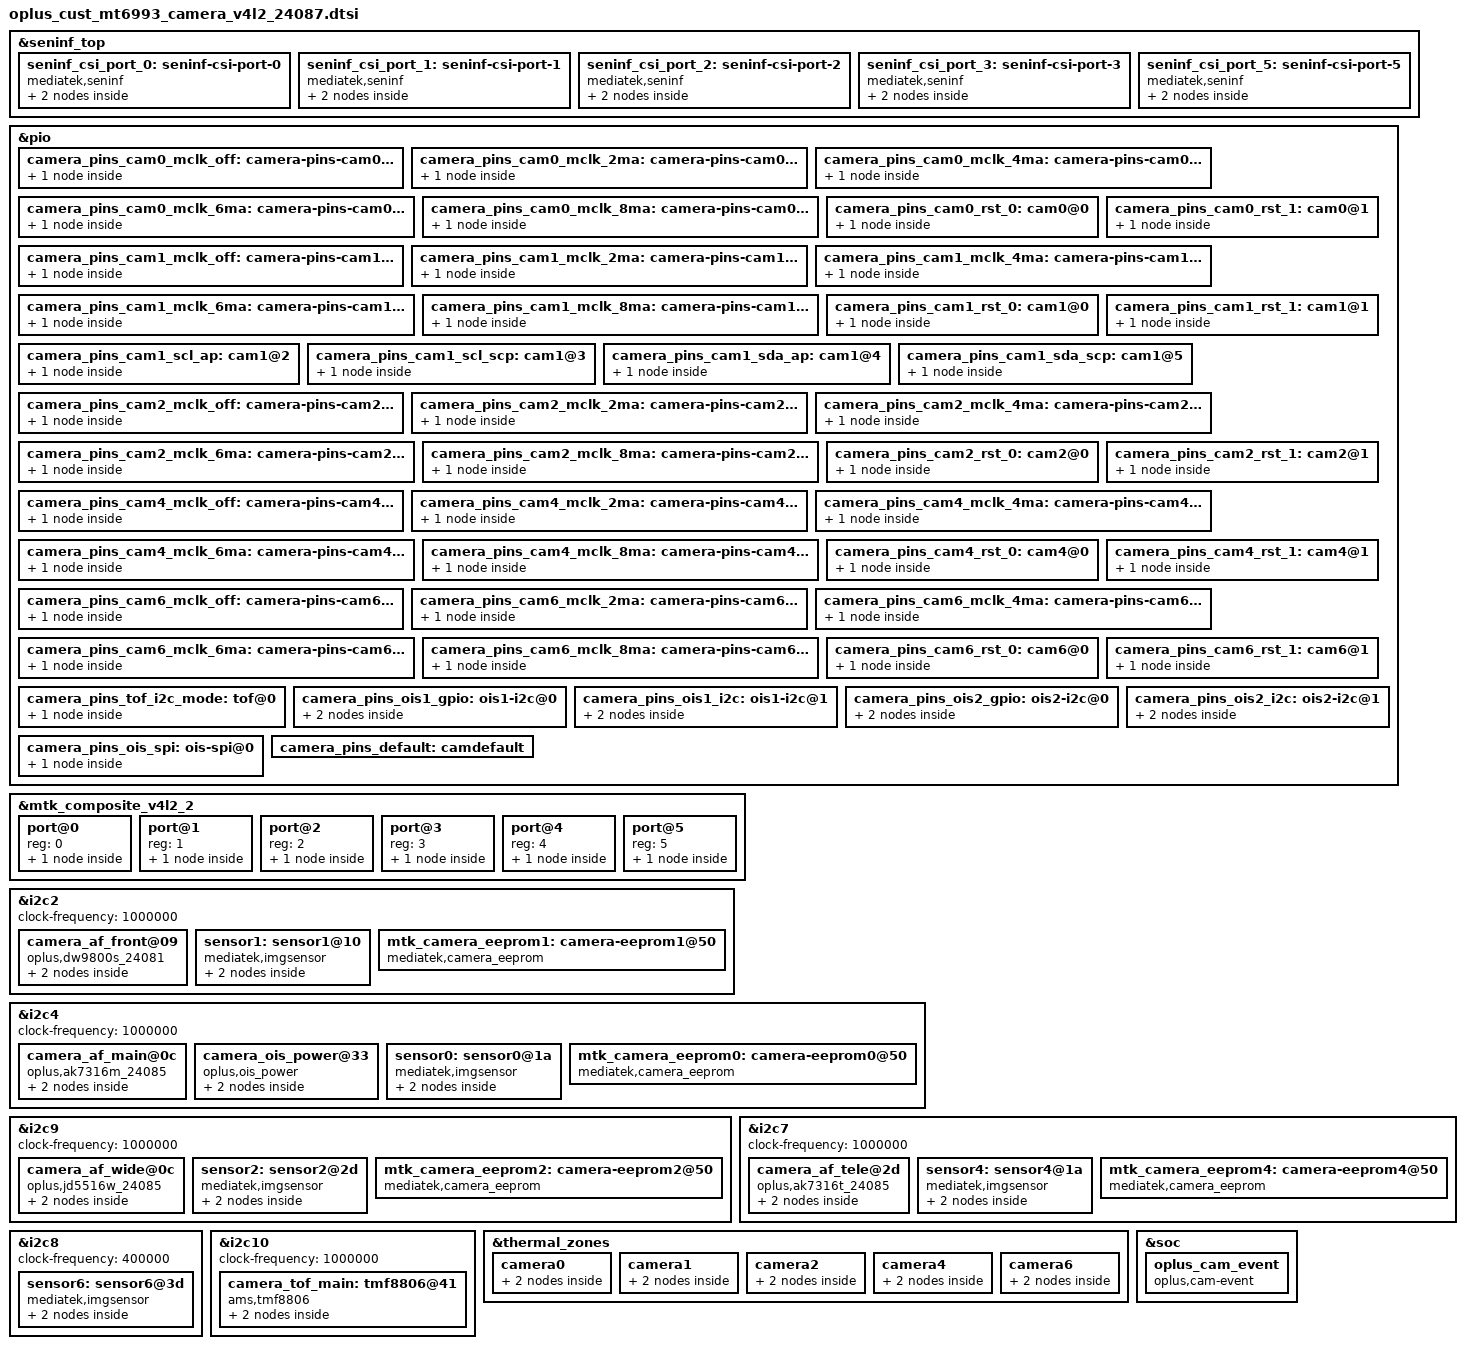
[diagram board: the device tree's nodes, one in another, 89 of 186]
// SPDX-License-Identifier: GPL-2.0
/* Copyright (c) 2023 MediaTek Inc. */
#include <dt-bindings/clock/mt6993-clk.h>
#include <dt-bindings/pinctrl/mt6993-pinfunc.h>
#include "oplus/oplus_camera_regulator_24085.dtsi"

&seninf_top {
		seninf_csi_port_0: seninf-csi-port-0 {
			compatible = "mediatek,seninf";
			csi-port = "0";

			nvmem-cells = <&csi_efuse0>;
			nvmem-cell-names = "rg_csi";

			port {
				seninf_csi_port_0_in: endpoint {
					remote-endpoint = <&sensor1_out>;
				};
			};
		};

		seninf_csi_port_1: seninf-csi-port-1 {
			compatible = "mediatek,seninf";
			csi-port = "1";

			nvmem-cells = <&csi_efuse1>;
			nvmem-cell-names = "rg_csi";

			port {
				seninf_csi_port_1_in: endpoint {
					remote-endpoint = <&sensor4_out>;
				};
			};
		};

		seninf_csi_port_2: seninf-csi-port-2 {
			compatible = "mediatek,seninf";
			csi-port = "2";

			nvmem-cells = <&csi_efuse2>;
			nvmem-cell-names = "rg_csi";

			port {
				seninf_csi_port_2_in: endpoint {
					remote-endpoint = <&sensor2_out>;
				};
			};
		};
		seninf_csi_port_3: seninf-csi-port-3 {
			compatible = "mediatek,seninf";
			csi-port = "3";

			nvmem-cells = <&csi_efuse3>;
			nvmem-cell-names = "rg_csi";

			port {
				seninf_csi_port_3_in: endpoint {
					remote-endpoint = <&sensor0_out>;
				};
			};
		};
		seninf_csi_port_5: seninf-csi-port-5 {
		 	compatible = "mediatek,seninf";
			csi-port = "5";

		 	nvmem-cells = <&csi_efuse5>;
		 	nvmem-cell-names = "rg_csi";

		 	port {
		 		seninf_csi_port_5_in: endpoint {
		 			remote-endpoint = <&sensor6_out>;
		 		};
		 	};
		};
};

/* CAMERA GPIO standardization */
&pio {
	camera_pins_cam0_mclk_off: camera-pins-cam0-mclk-off {
		pins-cmd-dat {
			pinmux = <PINMUX_GPIO208__FUNC_GPIO208>;
			drive-strength = <1>;
		};
	};

	camera_pins_cam0_mclk_2ma: camera-pins-cam0-mclk-2ma {
		pins-cmd-dat {
			pinmux = <PINMUX_GPIO208__FUNC_CMMCLK4>;
			drive-strength = <0>;
		};
	};

	camera_pins_cam0_mclk_4ma: camera-pins-cam0-mclk-4ma {
		pins-cmd-dat {
			pinmux = <PINMUX_GPIO208__FUNC_CMMCLK4>;
			drive-strength = <1>;
		};
	};

	camera_pins_cam0_mclk_6ma: camera-pins-cam0-mclk-6ma {
		pins-cmd-dat {
			pinmux = <PINMUX_GPIO208__FUNC_CMMCLK4>;
			drive-strength = <2>;
		};
	};

	camera_pins_cam0_mclk_8ma: camera-pins-cam0-mclk-8ma {
		pins-cmd-dat {
			pinmux = <PINMUX_GPIO208__FUNC_CMMCLK4>;
			drive-strength = <3>;
		};
	};

	camera_pins_cam0_rst_0: cam0@0 {
		pins-cmd-dat {
			pinmux = <PINMUX_GPIO171__FUNC_GPIO171>;
			slew-rate = <1>;
			output-low;
		};
	};
	camera_pins_cam0_rst_1: cam0@1 {
		pins-cmd-dat {
			pinmux = <PINMUX_GPIO171__FUNC_GPIO171>;
			slew-rate = <1>;
			output-high;
		};
	};
	// camera_pins_cam0_i2c_mode: cam0@2 {
	// 	pins-cmd-dat {
	// 		pinmux = <PINMUX_GPIO190__FUNC_SCL4>,
	// 		<PINMUX_GPIO191__FUNC_SDA4>;
	// 		bias-pull-up;
	// 		input-enable;
	// 	};
	// };
	camera_pins_cam1_mclk_off: camera-pins-cam1-mclk-off {
		pins-cmd-dat {
			pinmux = <PINMUX_GPIO72__FUNC_GPIO72>;
			drive-strength = <1>;
		};
	};
	camera_pins_cam1_mclk_2ma: camera-pins-cam1-mclk-2ma {
		pins-cmd-dat {
			pinmux = <PINMUX_GPIO72__FUNC_CMMCLK0>;
			drive-strength = <0>;
		};
	};
	camera_pins_cam1_mclk_4ma: camera-pins-cam1-mclk-4ma {
		pins-cmd-dat {
			pinmux = <PINMUX_GPIO72__FUNC_CMMCLK0>;
			drive-strength = <1>;
		};
	};
	camera_pins_cam1_mclk_6ma: camera-pins-cam1-mclk-6ma {
		pins-cmd-dat {
			pinmux = <PINMUX_GPIO72__FUNC_CMMCLK0>;
			drive-strength = <2>;
		};
	};
	camera_pins_cam1_mclk_8ma: camera-pins-cam1-mclk-8ma {
		pins-cmd-dat {
			pinmux = <PINMUX_GPIO72__FUNC_CMMCLK0>;
			drive-strength = <3>;
		};
	};
	camera_pins_cam1_rst_0: cam1@0 {
		pins-cmd-dat {
			pinmux = <PINMUX_GPIO170__FUNC_GPIO170>;
			slew-rate = <1>;
			output-low;
		};
	};
	camera_pins_cam1_rst_1: cam1@1 {
		pins-cmd-dat {
			pinmux = <PINMUX_GPIO170__FUNC_GPIO170>;
			slew-rate = <1>;
			output-high;
		};
	};
	camera_pins_cam1_scl_ap: cam1@2 {
		pins-cmd-dat {
			pinmux = <PINMUX_GPIO172__FUNC_SCL2>;
		};
	};
	camera_pins_cam1_scl_scp: cam1@3 {
		pins-cmd-dat {
			pinmux = <PINMUX_GPIO172__FUNC_SCP_SCL8>;
		};
	};
	camera_pins_cam1_sda_ap: cam1@4 {
		pins-cmd-dat {
			pinmux = <PINMUX_GPIO173__FUNC_SDA2>;
		};
	};
	camera_pins_cam1_sda_scp: cam1@5 {
		pins-cmd-dat {
			pinmux = <PINMUX_GPIO173__FUNC_SCP_SDA8>;
		};
	};
	camera_pins_cam2_mclk_off: camera-pins-cam2-mclk-off {
		pins-cmd-dat {
			pinmux = <PINMUX_GPIO192__FUNC_GPIO192>;
			drive-strength = <1>;
		};
	};
	camera_pins_cam2_mclk_2ma: camera-pins-cam2-mclk-2ma {
		pins-cmd-dat {
			pinmux = <PINMUX_GPIO192__FUNC_CMMCLK3>;
			drive-strength = <0>;
		};
	};
	camera_pins_cam2_mclk_4ma: camera-pins-cam2-mclk-4ma {
		pins-cmd-dat {
			pinmux = <PINMUX_GPIO192__FUNC_CMMCLK3>;
			drive-strength = <1>;
		};
	};
	camera_pins_cam2_mclk_6ma: camera-pins-cam2-mclk-6ma {
		pins-cmd-dat {
			pinmux = <PINMUX_GPIO192__FUNC_CMMCLK3>;
			drive-strength = <2>;
		};
	};
	camera_pins_cam2_mclk_8ma: camera-pins-cam2-mclk-8ma {
		pins-cmd-dat {
			pinmux = <PINMUX_GPIO192__FUNC_CMMCLK3>;
			drive-strength = <3>;
		};
	};
	camera_pins_cam2_rst_0: cam2@0 {
		pins-cmd-dat {
			pinmux = <PINMUX_GPIO205__FUNC_GPIO205>;
			slew-rate = <1>;
			output-low;
		};
	};
	camera_pins_cam2_rst_1: cam2@1 {
		pins-cmd-dat {
			pinmux = <PINMUX_GPIO205__FUNC_GPIO205>;
			slew-rate = <1>;
			output-high;
		};
	};

	camera_pins_cam4_mclk_off: camera-pins-cam4-mclk-off {
		pins-cmd-dat {
			pinmux = <PINMUX_GPIO188__FUNC_GPIO188>;
			drive-strength = <1>;
		};
	};
	camera_pins_cam4_mclk_2ma: camera-pins-cam4-mclk-2ma {
		pins-cmd-dat {
			pinmux = <PINMUX_GPIO188__FUNC_CMMCLK2>;
			drive-strength = <0>;
		};
	};
	camera_pins_cam4_mclk_4ma: camera-pins-cam4-mclk-4ma {
		pins-cmd-dat {
			pinmux = <PINMUX_GPIO188__FUNC_CMMCLK2>;
			drive-strength = <1>;
		};
	};
	camera_pins_cam4_mclk_6ma: camera-pins-cam4-mclk-6ma {
		pins-cmd-dat {
			pinmux = <PINMUX_GPIO188__FUNC_CMMCLK2>;
			drive-strength = <2>;
		};
	};
	camera_pins_cam4_mclk_8ma: camera-pins-cam4-mclk-8ma {
		pins-cmd-dat {
			pinmux = <PINMUX_GPIO188__FUNC_CMMCLK2>;
			drive-strength = <3>;
		};
	};
	camera_pins_cam4_rst_0: cam4@0 {
		pins-cmd-dat {
			pinmux = <PINMUX_GPIO189__FUNC_GPIO189>;
			slew-rate = <1>;
			output-low;
		};
	};
	camera_pins_cam4_rst_1: cam4@1 {
		pins-cmd-dat {
			pinmux = <PINMUX_GPIO189__FUNC_GPIO189>;
			slew-rate = <1>;
			output-high;
		};
	};

	camera_pins_cam6_mclk_off: camera-pins-cam6-mclk-off {
		pins-cmd-dat {
			pinmux = <PINMUX_GPIO209__FUNC_GPIO209>;
			drive-strength = <1>;
		};
	};
	camera_pins_cam6_mclk_2ma: camera-pins-cam6-mclk-2ma {
		pins-cmd-dat {
			pinmux = <PINMUX_GPIO209__FUNC_CMMCLK5>;
			drive-strength = <0>;
		};
	};
	camera_pins_cam6_mclk_4ma: camera-pins-cam6-mclk-4ma {
		pins-cmd-dat {
			pinmux = <PINMUX_GPIO209__FUNC_CMMCLK5>;
			drive-strength = <1>;
		};
	};
	camera_pins_cam6_mclk_6ma: camera-pins-cam6-mclk-6ma {
		pins-cmd-dat {
			pinmux = <PINMUX_GPIO209__FUNC_CMMCLK5>;
			drive-strength = <2>;
		};
	};
	camera_pins_cam6_mclk_8ma: camera-pins-cam6-mclk-8ma {
		pins-cmd-dat {
			pinmux = <PINMUX_GPIO209__FUNC_CMMCLK5>;
			drive-strength = <3>;
		};
	};
	camera_pins_cam6_rst_0: cam6@0 {
		pins-cmd-dat {
			pinmux = <PINMUX_GPIO204__FUNC_GPIO204>;
			slew-rate = <1>;
			output-low;
		};
	};
	camera_pins_cam6_rst_1: cam6@1 {
		pins-cmd-dat {
			pinmux = <PINMUX_GPIO204__FUNC_GPIO204>;
			slew-rate = <1>;
			output-high;
		};
	};
	camera_pins_tof_i2c_mode: tof@0 {
		pins-cmd-dat {
			pinmux = <PINMUX_GPIO116__FUNC_SCL10>,
			<PINMUX_GPIO117__FUNC_SDA10>,
			<PINMUX_GPIO22__FUNC_GPIO22>;
			bias-pull-up;
			input-enable;
		};
	};
	camera_pins_ois1_gpio: ois1-i2c@0 {
		pins-cmd-scl {
			pinmux = < PINMUX_GPIO218__FUNC_GPIO218>;
			slew-rate = <1>;
			output-low;
		};
		pins-cmd-sda {
			pinmux = < PINMUX_GPIO219__FUNC_GPIO219>;
			slew-rate = <1>;
			output-low;
		};
	};
	camera_pins_ois1_i2c: ois1-i2c@1 {
		pins-cmd-scl {
			pinmux = <PINMUX_GPIO218__FUNC_SCP_SCL4_OIS>;
			bias-pull-up;
		};
		pins-cmd-sda {
			pinmux = <PINMUX_GPIO219__FUNC_SCP_SDA4_OIS>;
			bias-pull-up;
		};
	};
	camera_pins_ois2_gpio: ois2-i2c@0 {
		pins-cmd-scl {
			pinmux = < PINMUX_GPIO220__FUNC_GPIO220>;
			slew-rate = <1>;
			output-low;
		};
		pins-cmd-sda {
			pinmux = < PINMUX_GPIO221__FUNC_GPIO221>;
			slew-rate = <1>;
			output-low;
		};
	};
	camera_pins_ois2_i2c: ois2-i2c@1 {
		pins-cmd-scl {
			pinmux = <PINMUX_GPIO220__FUNC_SCP_SCL5_OIS>;
			bias-pull-up;
		};
		pins-cmd-sda {
			pinmux = <PINMUX_GPIO221__FUNC_SCP_SDA5_OIS>;
			bias-pull-up;
		};
	};
	camera_pins_ois_spi: ois-spi@0 {
		pins-cmd-spi {
			pinmux = <PINMUX_GPIO164__FUNC_GPIO164>,
					<PINMUX_GPIO165__FUNC_GPIO165>,
					<PINMUX_GPIO166__FUNC_GPIO166>,
					<PINMUX_GPIO167__FUNC_GPIO167>;
			drive-strength = <0>;
			bias-pull-down;
		};
	};
	camera_pins_default: camdefault {
	};
};
/* CAMERA GPIO end */

// &odm {
// 	camera_pins_cam6_avdd: camera-pins-cam6-avdd {
// 		compatible = "regulator-fixed";
// 		regulator-name = "camera-pins-cam6-avdd";
// 		regulator-min-microvolt = <2800000>;
// 		regulator-max-microvolt = <2800000>;
// 		enable-active-high;
// 		gpio = <&pio 183 0x0>;
// 	};
// 	camera_pins_cam6_oisvdd: camera-pins-cam6-oisvdd {
// 		compatible = "regulator-fixed";
// 		regulator-name = "camera-pins-cam6-oisvdd";
// 		regulator-min-microvolt = <3100000>;
// 		regulator-max-microvolt = <3100000>;
// 		enable-active-high;
// 		gpio = <&pio 180 0x0>;
// 	};
// };

&mtk_composite_v4l2_2 {

	#address-cells = <1>;
	#size-cells = <0>;

	port@0 {
		reg = <0>;
		main_af_endpoint: endpoint {
			remote-endpoint = <&main_af>;
		};
	};
	port@1 {
		reg = <1>;
		wide_af_endpoint: endpoint {
			remote-endpoint = <&wide_af>;
		};
	};
	port@2 {
		reg = <2>;
		tele_af_endpoint: endpoint {
			remote-endpoint = <&tele_af>;
		};
	};
	port@3 {
		reg = <3>;
		main_tof_endpoint: endpoint {
			remote-endpoint = <&main_tof>;
		};
	};
	port@4 {
		reg = <4>;
		ois_power_endpoint: endpoint {
			remote-endpoint = <&ois_power>;
		};
	};
	port@5 {
		reg = <5>;
		front_af_endpoint: endpoint {
			remote-endpoint = <&front_af>;
		};
	};
};


&i2c2 {
	status = "okay";
	clock-frequency = <1000000>;
	#address-cells = <1>;
	#size-cells = <0>;

	camera_af_front@09 {
		compatible = "oplus,dw9800s_24081";
		reg = <0x09>;
		vin-supply = <&mt6661_5_ldc0_4>;
		port {
			front_af: endpoint {
				remote-endpoint = <&front_af_endpoint>;
			};
		};
	};

	sensor1: sensor1@10 {
		compatible = "mediatek,imgsensor";
		sensor-names = "hhfront_mipi_raw", "cjfront_mipi_raw";
		reg = <0x10>;
		#thermal-sensor-cells = <0>;

		pinctrl-names = "mclk_off",
				"mclk_2mA",
				"mclk_4mA",
				"mclk_6mA",
				"mclk_8mA",
				"rst_low",
				"rst_high",
				"scl_ap",
				"scl_scp",
				"sda_ap",
				"sda_scp";

		pinctrl-0 = <&camera_pins_cam1_mclk_off>;
		pinctrl-1 = <&camera_pins_cam1_mclk_2ma>;
		pinctrl-2 = <&camera_pins_cam1_mclk_4ma>;
		pinctrl-3 = <&camera_pins_cam1_mclk_6ma>;
		pinctrl-4 = <&camera_pins_cam1_mclk_8ma>;
		pinctrl-5 = <&camera_pins_cam1_rst_0>;
		pinctrl-6 = <&camera_pins_cam1_rst_1>;
		pinctrl-7 = <&camera_pins_cam1_scl_ap>;
		pinctrl-8 = <&camera_pins_cam1_scl_scp>;
		pinctrl-9 = <&camera_pins_cam1_sda_ap>;
		pinctrl-10 = <&camera_pins_cam1_sda_scp>;

		avdd-supply = <&wl28681c_hh_ldo3a>;
		dvdd-supply = <&wl28681c_hh_ldo1a>;
		dovdd-supply = <&mt6661_3_ln60_7>;
		afvdd-supply = <&mt6661_5_ldc0_4>;

		clocks = <&cksys_top_clk CKSYS_TOP_UNIVPLL_192M_D32>,
			<&cksys_top_clk CKSYS_TOP_UNIVPLL_192M_D16>,
			<&cksys_top_clk CKSYS_VLP_F26M_CK_D2>,
			<&cksys_top_clk CKSYS_TOP_UNIVPLL_192M_D10>,
			<&cksys_top_clk CKSYS_TOP_UNIVPLL_192M_D8>,
			<&cksys_top_clk CKSYS_TOP_UNIVPLL_D6_D16>,
			<&cksys_top_clk CKSYS_TOP_OSC_D20>,
			<&cksys_top_clk CKSYS_TOP_UNIVPLL_D6_D8>,
			<&cksys_vlp_clk VLP_CAMTG0_SEL>;
		clock-names = "6", "12", "13", "19.2", "24", "26", "26_ulposc", "52", "mclk";

		status = "okay";
		port {
			sensor1_out: endpoint {
				remote-endpoint = <&seninf_csi_port_0_in>;
			};
		};
	};

	mtk_camera_eeprom1:camera-eeprom1@50 {
		compatible = "mediatek,camera_eeprom";
		reg = <0x54>;
		names = "hhfront_op_eeprom", "cjfront_op_eeprom";
		status = "okay";
	};
};


&i2c4 {
	status = "okay";
	clock-frequency = <1000000>;
	#address-cells = <1>;
	#size-cells = <0>;

	camera_af_main@0c {
		compatible = "oplus,ak7316m_24085";
		reg = <0x0c>;
		vin-supply = <&mt6661_6_ldc0_3>;
		port {
			main_af: endpoint {
				remote-endpoint = <&main_af_endpoint>;
			};
		};
	};

	camera_ois_power@33 {
		compatible = "oplus,ois_power";
		reg = <0x33>;
		ois1-supply = <&mt6661_6_ldc0_3>;
		ois1-supply-vol = <3000000>;
		ois2-supply = <&mt6661_3_ldc0_4>;
		ois2-supply-vol = <3100000>;
		iovdd-supply = <&mt6661_3_ln60_7>;
		iovdd-supply-vol = <1800000>;
		pinctrl-names = "ois1_gpio",
			"ois1_i2c",
			"ois2_gpio",
			"ois2_i2c",
			"default";
		pinctrl-0 = <&camera_pins_ois1_gpio>;
		pinctrl-1 = <&camera_pins_ois1_i2c>;
		pinctrl-2 = <&camera_pins_ois2_gpio>;
		pinctrl-3 = <&camera_pins_ois2_i2c>;
		pinctrl-4 = <&camera_pins_ois_spi>;
		port {
			ois_power: endpoint {
				remote-endpoint = <&ois_power_endpoint>;
			};
		};
	};

	sensor0: sensor0@1a {
		compatible = "mediatek,imgsensor";
		sensor-names = "hhmain_mipi_raw", "cjmain_mipi_raw";
		reg = <0x1a>;
		#thermal-sensor-cells = <0>;

		pinctrl-names = "mclk_off",
				"mclk_2mA",
				"mclk_4mA",
				"mclk_6mA",
				"mclk_8mA",
				"rst_low",
				"rst_high";
				// "default";
		pinctrl-0 = <&camera_pins_cam0_mclk_off>;
		pinctrl-1 = <&camera_pins_cam0_mclk_2ma>;
		pinctrl-2 = <&camera_pins_cam0_mclk_4ma>;
		pinctrl-3 = <&camera_pins_cam0_mclk_6ma>;
		pinctrl-4 = <&camera_pins_cam0_mclk_8ma>;
		pinctrl-5 = <&camera_pins_cam0_rst_0>;
		pinctrl-6 = <&camera_pins_cam0_rst_1>;
		// pinctrl-7 = <&camera_pins_cam0_i2c_mode>;

		avdd1-supply = <&wl28681c_hh_ldo7a>;
		avdd-supply = <&wl28681c_hh_ldo4a>;
		dvdd-supply = <&wl28681c_hh_ldo2a>;
		dovdd-supply = <&mt6661_3_ln60_7>;
		afvdd-supply = <&mt6661_6_ldc0_3>;

		mediatek,vs-voter = <&mt6661_3 0x178A 0x04 1>;

		clocks = <&cksys_top_clk CKSYS_TOP_UNIVPLL_192M_D32>,
			<&cksys_top_clk CKSYS_TOP_UNIVPLL_192M_D16>,
			<&cksys_top_clk CKSYS_VLP_F26M_CK_D2>,
			<&cksys_top_clk CKSYS_TOP_UNIVPLL_192M_D10>,
			<&cksys_top_clk CKSYS_TOP_UNIVPLL_192M_D8>,
			<&cksys_top_clk CKSYS_TOP_UNIVPLL_D6_D16>,
			<&cksys_top_clk CKSYS_TOP_UNIVPLL_D6_D8>,
			<&cksys_vlp_clk VLP_CAMTG4_SEL>;
		clock-names = "6", "12", "13", "19.2", "24", "26", "52", "mclk";

		status = "okay";

		port {
			sensor0_out: endpoint {
				remote-endpoint = <&seninf_csi_port_3_in>;
			};
		};
	};

	mtk_camera_eeprom0:camera-eeprom0@50 {
		compatible = "mediatek,camera_eeprom";
		reg = <0x50>;
		names = "hhmain_op_eeprom", "cjmain_op_eeprom";
		status = "okay";
	};
};

&i2c9 {
	status = "okay";
	clock-frequency = <1000000>;
	#address-cells = <1>;
	#size-cells = <0>;

	camera_af_wide@0c {
		compatible = "oplus,jd5516w_24085";
		reg = <0x0c>;
		vin-supply = <&mt6661_5_ldc0_4>;
		port {
			wide_af: endpoint {
				remote-endpoint = <&wide_af_endpoint>;
			};
		};
	};

	sensor2: sensor2@2d {
		compatible = "mediatek,imgsensor";
		sensor-names = "hhuwide_mipi_raw";
		reg = <0x2d>;
		#thermal-sensor-cells = <0>;

		pinctrl-names = "mclk_off",
				"mclk_2mA",
				"mclk_4mA",
				"mclk_6mA",
				"mclk_8mA",
				"rst_low",
				"rst_high";
		pinctrl-0 = <&camera_pins_cam2_mclk_off>;
		pinctrl-1 = <&camera_pins_cam2_mclk_2ma>;
		pinctrl-2 = <&camera_pins_cam2_mclk_4ma>;
		pinctrl-3 = <&camera_pins_cam2_mclk_6ma>;
		pinctrl-4 = <&camera_pins_cam2_mclk_8ma>;
		pinctrl-5 = <&camera_pins_cam2_rst_0>;
		pinctrl-6 = <&camera_pins_cam2_rst_1>;

		avdd-supply = <&wl28681c_hh_ldo6a>;
		dvdd-supply = <&mt6661_5_lnc0_10>;
		dvdd1-supply = <&mt6661_5_lnc0_10>;
		dovdd-supply = <&mt6661_3_ln60_7>;
		afvdd-supply = <&mt6661_5_ldc0_4>;

		clocks = <&cksys_top_clk CKSYS_TOP_UNIVPLL_192M_D32>,
			<&cksys_top_clk CKSYS_TOP_UNIVPLL_192M_D16>,
			<&cksys_top_clk CKSYS_VLP_F26M_CK_D2>,
			<&cksys_top_clk CKSYS_TOP_UNIVPLL_192M_D10>,
			<&cksys_top_clk CKSYS_TOP_UNIVPLL_192M_D8>,
			<&cksys_top_clk CKSYS_TOP_UNIVPLL_D6_D16>,
			<&cksys_top_clk CKSYS_TOP_UNIVPLL_D6_D8>,
			<&cksys_vlp_clk VLP_CAMTG3_SEL>;
		clock-names = "6", "12", "13", "19.2", "24", "26", "52", "mclk";

		ob-version = "zj";

		status = "okay";

		port {
			sensor2_out: endpoint {
				remote-endpoint = <&seninf_csi_port_2_in>;
			};
		};
	};

	mtk_camera_eeprom2:camera-eeprom2@50 {
		compatible = "mediatek,camera_eeprom";
		names = "hhuwide_op_eeprom";
		reg = <0x50>;
		status = "okay";
	};
};


&i2c7 {
	status = "okay";
	clock-frequency = <1000000>;
	#address-cells = <1>;
	#size-cells = <0>;

	camera_af_tele@2d {
		compatible = "oplus,ak7316t_24085";
		reg = <0x2d>;
		vin-supply = <&mt6661_3_ldc0_4>;
		port {
			tele_af: endpoint {
				remote-endpoint = <&tele_af_endpoint>;
			};
		};
	};

	sensor4: sensor4@1a {
		compatible = "mediatek,imgsensor";
		sensor-names = "hhtele_mipi_raw";
		reg = <0x1a>;
		#thermal-sensor-cells = <0>;

		pinctrl-names = "mclk_off",
				"mclk_2mA",
				"mclk_4mA",
				"mclk_6mA",
				"mclk_8mA",
				"rst_low",
				"rst_high";
		pinctrl-0 = <&camera_pins_cam4_mclk_off>;
		pinctrl-1 = <&camera_pins_cam4_mclk_2ma>;
		pinctrl-2 = <&camera_pins_cam4_mclk_4ma>;
		pinctrl-3 = <&camera_pins_cam4_mclk_6ma>;
		pinctrl-4 = <&camera_pins_cam4_mclk_8ma>;
		pinctrl-5 = <&camera_pins_cam4_rst_0>;
		pinctrl-6 = <&camera_pins_cam4_rst_1>;

		avdd-supply = <&wl28681c_hh_ldo5a>;
		dvdd-supply = <&wl28681c_hh_ldo1a>;
		dovdd-supply = <&mt6661_3_ln60_7>;
		afvdd-supply = <&mt6661_3_ldc0_4>;

		clocks = <&cksys_top_clk CKSYS_TOP_UNIVPLL_192M_D32>,
			<&cksys_top_clk CKSYS_TOP_UNIVPLL_192M_D16>,
			<&cksys_top_clk CKSYS_VLP_F26M_CK_D2>,
			<&cksys_top_clk CKSYS_TOP_UNIVPLL_192M_D10>,
			<&cksys_top_clk CKSYS_TOP_UNIVPLL_192M_D8>,
			<&cksys_top_clk CKSYS_TOP_UNIVPLL_D6_D16>,
			<&cksys_top_clk CKSYS_TOP_UNIVPLL_D6_D8>,
			<&cksys_vlp_clk VLP_CAMTG2_SEL>;
		clock-names = "6", "12", "13", "19.2", "24", "26", "52", "mclk";

		status = "okay";

		port {
			sensor4_out: endpoint {
				remote-endpoint = <&seninf_csi_port_1_in>;
			};
		};
	};

	mtk_camera_eeprom4:camera-eeprom4@50 {
		compatible = "mediatek,camera_eeprom";
		names = "hhtele_op_eeprom";
		reg = <0x50>;
		status = "okay";
	};
};

&i2c8 {
	status = "okay";
	clock-frequency = <400000>;
	#address-cells = <1>;
	#size-cells = <0>;

	sensor6: sensor6@3d {
		compatible = "mediatek,imgsensor";
		sensor-names = "hhmwcs_mipi_raw";
		reg = <0x3d>;
		#thermal-sensor-cells = <0>;

		pinctrl-names = "mclk_off",
				"mclk_2mA",
				"mclk_4mA",
				"mclk_6mA",
				"mclk_8mA",
				"rst_low",
				"rst_high";
		pinctrl-0 = <&camera_pins_cam6_mclk_off>;
		pinctrl-1 = <&camera_pins_cam6_mclk_2ma>;
		pinctrl-2 = <&camera_pins_cam6_mclk_4ma>;
		pinctrl-3 = <&camera_pins_cam6_mclk_6ma>;
		pinctrl-4 = <&camera_pins_cam6_mclk_8ma>;
		pinctrl-5 = <&camera_pins_cam6_rst_0>;
		pinctrl-6 = <&camera_pins_cam6_rst_1>;

		avdd-supply = <&wl28681c_hh_ldo3a>;
		avdd1-supply = <&wl28681c_hh_ldo3a>;
		dovdd-supply = <&mt6661_3_ln60_7>;
		io-channels = <&mt6661_5_auxadc AUXADC_VIN5_POLL>;
		io-channel-names = "temperature-channel";

		clocks = <&cksys_top_clk CKSYS_TOP_UNIVPLL_192M_D32>,
			<&cksys_top_clk CKSYS_TOP_UNIVPLL_192M_D16>,
			<&cksys_top_clk CKSYS_VLP_F26M_CK_D2>,
			<&cksys_top_clk CKSYS_TOP_UNIVPLL_192M_D10>,
			<&cksys_top_clk CKSYS_TOP_UNIVPLL_192M_D8>,
			<&cksys_top_clk CKSYS_TOP_UNIVPLL_D6_D16>,
			<&cksys_top_clk CKSYS_TOP_UNIVPLL_D6_D8>,
			<&cksys_vlp_clk VLP_CAMTG5_SEL>;
		clock-names = "6", "12", "13", "19.2", "24", "26", "52", "mclk";

		status = "okay";

		port {
			sensor6_out: endpoint {
				remote-endpoint = <&seninf_csi_port_5_in>;
			};
		};
	};
};

&i2c10 {
	clock-frequency = <1000000>;
	#address-cells = <1>;
	#size-cells = <0>;
	camera_tof_main:tmf8806@41 {
		compatible = "ams,tmf8806";
		pinctrl-names = "default";
		pinctrl-0 = <&camera_pins_tof_i2c_mode>;
		#address-cells = <1>;
		#size-cells = <0>;
		reg = <0x41>;
		enable-gpio = <&pio 22 0x0>;
		poll_period = <0xA>;    /* poll period (100 usec) */
		port {
			main_tof: endpoint {
				remote-endpoint = <&main_tof_endpoint>;
			};
		};
	};
};

&thermal_zones {
	camera0: camera0 {
		polling-delay = <0>; /* milliseconds */
		polling-delay-passive = <0>; /* milliseconds */
		thermal-sensors = <&sensor0>;
		trips {
			camera0_crit: camera0-crit {
				temperature = <120000>;
				hysteresis = <2000>;
				type = "passive";
			};
		};
	};
	camera1: camera1 {
		polling-delay = <0>; /* milliseconds */
		polling-delay-passive = <0>; /* milliseconds */
		thermal-sensors = <&sensor1>;
		trips {
			camera1_crit: camera1-crit {
				temperature = <120000>;
				hysteresis = <2000>;
				type = "passive";
			};
		};
	};
	camera2: camera2 {
		polling-delay = <0>; /* milliseconds */
		polling-delay-passive = <0>; /* milliseconds */
		thermal-sensors = <&sensor2>;
		trips {
			camera2_crit: camera2-crit {
				temperature = <120000>;
				hysteresis = <2000>;
				type = "passive";
			};
		};
	};
	camera4: camera4 {
		polling-delay = <0>; /* milliseconds */
		polling-delay-passive = <0>; /* milliseconds */
		thermal-sensors = <&sensor4>;
		trips {
			camera4_crit: camera4-crit {
				temperature = <120000>;
				hysteresis = <2000>;
				type = "passive";
			};
		};
	};
	camera6: camera6 {
		polling-delay = <0>;
		polling-delay-passive = <0>;
		thermal-sensors = <&sensor6>;
		trips {
			camera6_crit: camera6-crit {
				temperature = <120000>;
				hysteresis = <2000>;
				type = "passive";
			};
		};
	};
};

&soc {
	//#ifdef OPLUS_FEATURE_CAMERA_COMMON
	oplus_cam_event:oplus_cam_event {
		compatible = "oplus,cam-event";
	};
	//#endif /* OPLUS_FEATURE_CAMERA_COMMON */
};
